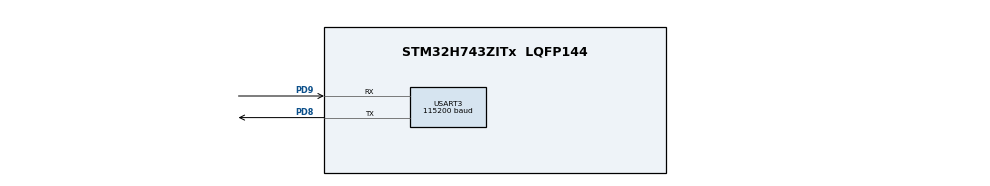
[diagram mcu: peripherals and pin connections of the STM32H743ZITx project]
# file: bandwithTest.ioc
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CORTEX_M7.default_mode_Activation=1
Dma.Request0=USART3_RX
Dma.Request1=USART3_TX
Dma.USART3_RX.0.Direction=DMA_PERIPH_TO_MEMORY
Dma.USART3_RX.0.EventEnable=DISABLE
Dma.USART3_RX.0.FIFOMode=DMA_FIFOMODE_DISABLE
Dma.USART3_RX.0.Instance=DMA1_Stream0
Dma.USART3_RX.0.MemDataAlignment=DMA_MDATAALIGN_BYTE
Dma.USART3_RX.0.MemInc=DMA_MINC_ENABLE
Dma.USART3_RX.0.Mode=DMA_NORMAL
Dma.USART3_RX.0.PeriphDataAlignment=DMA_PDATAALIGN_BYTE
Dma.USART3_RX.0.PeriphInc=DMA_PINC_DISABLE
Dma.USART3_RX.0.Polarity=HAL_DMAMUX_REQ_GEN_RISING
Dma.USART3_RX.0.Priority=DMA_PRIORITY_LOW
Dma.USART3_RX.0.RequestNumber=1
Dma.USART3_RX.0.SignalID=NONE
Dma.USART3_RX.0.SyncEnable=DISABLE
Dma.USART3_RX.0.SyncPolarity=HAL_DMAMUX_SYNC_NO_EVENT
Dma.USART3_RX.0.SyncRequestNumber=1
Dma.USART3_RX.0.SyncSignalID=NONE
Dma.USART3_TX.1.Direction=DMA_MEMORY_TO_PERIPH
Dma.USART3_TX.1.EventEnable=DISABLE
Dma.USART3_TX.1.FIFOMode=DMA_FIFOMODE_DISABLE
Dma.USART3_TX.1.Instance=DMA1_Stream1
Dma.USART3_TX.1.MemDataAlignment=DMA_MDATAALIGN_BYTE
Dma.USART3_TX.1.MemInc=DMA_MINC_ENABLE
Dma.USART3_TX.1.Mode=DMA_NORMAL
Dma.USART3_TX.1.PeriphDataAlignment=DMA_PDATAALIGN_BYTE
Dma.USART3_TX.1.PeriphInc=DMA_PINC_DISABLE
Dma.USART3_TX.1.Polarity=HAL_DMAMUX_REQ_GEN_RISING
Dma.USART3_TX.1.Priority=DMA_PRIORITY_LOW
Dma.USART3_TX.1.RequestNumber=1
Dma.USART3_TX.1.SignalID=NONE
Dma.USART3_TX.1.SyncEnable=DISABLE
Dma.USART3_TX.1.SyncPolarity=HAL_DMAMUX_SYNC_NO_EVENT
Dma.USART3_TX.1.SyncRequestNumber=1
Dma.USART3_TX.1.SyncSignalID=NONE
Mcu.Family=STM32H7
Mcu.Name=STM32H743ZITx
Mcu.Package=LQFP144
NUCLEO-H743ZI2.BUTTON=1
NUCLEO-H743ZI2.LD1=true
NUCLEO-H743ZI2.LD2=true
NUCLEO-H743ZI2.LD3=true
NUCLEO-H743ZI2.VCP=false
NVIC.DMA1_Stream0_IRQn=true\:0\:0\:false\:false\:true\:false\:true\:true
NVIC.DMA1_Stream1_IRQn=true\:0\:0\:false\:false\:true\:false\:true\:true
NVIC.EXTI15_10_IRQn=true\:0\:0\:false\:false\:true\:false\:true\:true
NVIC.PriorityGroup=NVIC_PRIORITYGROUP_4
NVIC.USART3_IRQn=true\:0\:0\:false\:false\:true\:true\:true\:true
PA13\ (JTMS/SWDIO).GPIO_Label=JTMS
PA13\ (JTMS/SWDIO).Mode=Serial_Wire
PA13\ (JTMS/SWDIO).Signal=DEBUG_JTMS-SWDIO
PA14\ (JTCK/SWCLK).GPIO_Label=JTCK
PA14\ (JTCK/SWCLK).Mode=Serial_Wire
PA14\ (JTCK/SWCLK).Signal=DEBUG_JTCK-SWCLK
PC14-OSC32_IN\ (OSC32_IN).Signal=RCC_OSC32_IN
PC15-OSC32_OUT\ (OSC32_OUT).Signal=RCC_OSC32_OUT
PD8.Mode=Asynchronous
PD8.Signal=USART3_TX
PD9.Mode=Asynchronous
PD9.Signal=USART3_RX
PH0-OSC_IN\ (PH0).Mode=HSE-External-Clock-Source
PH0-OSC_IN\ (PH0).Signal=RCC_OSC_IN
PH1-OSC_OUT\ (PH1).Signal=RCC_OSC_OUT
ProjectManager.HeapSize=0x200
ProjectManager.StackSize=0x400
ProjectManager.TargetToolchain=CMake
RCC.ADCFreq_Value=125000000
RCC.APB1Freq_Value=120000000
RCC.APB2Freq_Value=120000000
RCC.APB3Freq_Value=120000000
RCC.APB4Freq_Value=120000000
RCC.CortexFreq_Value=480000000
RCC.D1PPRE=RCC_APB3_DIV2
RCC.D2PPRE1=RCC_APB1_DIV2
RCC.D2PPRE2=RCC_APB2_DIV2
RCC.D3PPRE=RCC_APB4_DIV2
RCC.DIVM1=1
RCC.DIVM2=1
RCC.DIVN1=120
RCC.DIVN2=31
RCC.HCLKFreq_Value=240000000
RCC.HPRE=RCC_HCLK_DIV2
RCC.HSE_VALUE=8000000
RCC.PLL2FRACN=2048
RCC.PLLFRACN=0
RCC.PLLSourceVirtual=RCC_PLLSOURCE_HSE
RCC.SYSCLKFreq_VALUE=480000000
RCC.SYSCLKSource=RCC_SYSCLKSOURCE_PLLCLK
RCC.USART234578CLockSelection=RCC_USART234578CLKSOURCE_PLL2
RCC.USBFreq_Value=480000000
USART3.BaudRate=115200
USART3.VirtualMode-Asynchronous=VM_ASYNC
VP_MEMORYMAP_VS_MEMORYMAP.Mode=CurAppReg
VP_NUCLEO-H743ZI2_VS_BSP_COMMON.Mode=COMMON
board=NUCLEO-H743ZI2

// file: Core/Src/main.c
/* USER CODE BEGIN Header */
/**
  ******************************************************************************
  * @file           : main.c
  * @brief          : Main program body
  ******************************************************************************
  * @attention
  *
  * Copyright (c) 2026 STMicroelectronics.
  * All rights reserved.
  *
  * This software is licensed under terms that can be found in the LICENSE file
  * in the root directory of this software component.
  * If no LICENSE file comes with this software, it is provided AS-IS.
  *
  ******************************************************************************
  */
/* USER CODE END Header */
#include "main.h"
#include "dma.h"
#include "usart.h"
#include "gpio.h"

/* USER CODE BEGIN PD */

  int8_t *RxFrame = (uint8_t *)0x30000000;
  uint8_t *TxFrame = (uint8_t *)0x30010000;
  extern DMA_HandleTypeDef hdma_usart3_rx;
/* USER CODE END PD */

void SystemClock_Config(void);
static void MPU_Config(void);

int main(void)
{

  /* MPU Configuration--------------------------------------------------------*/
  MPU_Config();

  /* MCU Configuration--------------------------------------------------------*/

  /* Reset of all peripherals, Initializes the Flash interface and the Systick. */
  HAL_Init();

  /* Configure the system clock */
  SystemClock_Config();

  /* Initialize all configured peripherals */
  MX_GPIO_Init();
  MX_DMA_Init();
  MX_USART3_UART_Init();
  /* USER CODE BEGIN 2 */
  __HAL_UART_CLEAR_FLAG(&huart3, UART_CLEAR_OREF | UART_CLEAR_NEF | UART_CLEAR_PEF | UART_CLEAR_FEF);

  __HAL_UART_SEND_REQ(&huart3, UART_RXDATA_FLUSH_REQUEST);

  HAL_UARTEx_ReceiveToIdle_DMA(&huart3, RxFrame, FRAME_LENGHT);

  __HAL_DMA_DISABLE_IT(&hdma_usart3_rx, DMA_IT_HT);
  /* USER CODE END 2 */

  /* Initialize leds */
  BSP_LED_Init(LED_GREEN);
  BSP_LED_Init(LED_YELLOW);
  BSP_LED_Init(LED_RED);

  /* Initialize USER push-button, will be used to trigger an interrupt each time it's pressed.*/
  BSP_PB_Init(BUTTON_USER, BUTTON_MODE_EXTI);

  /* Infinite loop */
  while (1)
  {

  }
}

void SystemClock_Config(void)
{
  RCC_OscInitTypeDef RCC_OscInitStruct = {0};
  RCC_ClkInitTypeDef RCC_ClkInitStruct = {0};

  /** Supply configuration update enable
  */
  HAL_PWREx_ConfigSupply(PWR_LDO_SUPPLY);

  /** Configure the main internal regulator output voltage
  */
  __HAL_PWR_VOLTAGESCALING_CONFIG(PWR_REGULATOR_VOLTAGE_SCALE0);

  while(!__HAL_PWR_GET_FLAG(PWR_FLAG_VOSRDY)) {}

  /** Initializes the RCC Oscillators according to the specified parameters
  * in the RCC_OscInitTypeDef structure.
  */
  RCC_OscInitStruct.OscillatorType = RCC_OSCILLATORTYPE_HSE;
  RCC_OscInitStruct.HSEState = RCC_HSE_BYPASS;
  RCC_OscInitStruct.PLL.PLLState = RCC_PLL_ON;
  RCC_OscInitStruct.PLL.PLLSource = RCC_PLLSOURCE_HSE;
  RCC_OscInitStruct.PLL.PLLM = 1;
  RCC_OscInitStruct.PLL.PLLN = 120;
  RCC_OscInitStruct.PLL.PLLP = 2;
  RCC_OscInitStruct.PLL.PLLQ = 2;
  RCC_OscInitStruct.PLL.PLLR = 2;
  RCC_OscInitStruct.PLL.PLLRGE = RCC_PLL1VCIRANGE_3;
  RCC_OscInitStruct.PLL.PLLVCOSEL = RCC_PLL1VCOWIDE;
  RCC_OscInitStruct.PLL.PLLFRACN = 0;
  if (HAL_RCC_OscConfig(&RCC_OscInitStruct) != HAL_OK)
  {
    Error_Handler();
  }

  /** Initializes the CPU, AHB and APB buses clocks
  */
  RCC_ClkInitStruct.ClockType = RCC_CLOCKTYPE_HCLK|RCC_CLOCKTYPE_SYSCLK
                              |RCC_CLOCKTYPE_PCLK1|RCC_CLOCKTYPE_PCLK2
                              |RCC_CLOCKTYPE_D3PCLK1|RCC_CLOCKTYPE_D1PCLK1;
  RCC_ClkInitStruct.SYSCLKSource = RCC_SYSCLKSOURCE_PLLCLK;
  RCC_ClkInitStruct.SYSCLKDivider = RCC_SYSCLK_DIV1;
  RCC_ClkInitStruct.AHBCLKDivider = RCC_HCLK_DIV2;
  RCC_ClkInitStruct.APB3CLKDivider = RCC_APB3_DIV2;
  RCC_ClkInitStruct.APB1CLKDivider = RCC_APB1_DIV2;
  RCC_ClkInitStruct.APB2CLKDivider = RCC_APB2_DIV2;
  RCC_ClkInitStruct.APB4CLKDivider = RCC_APB4_DIV2;

  if (HAL_RCC_ClockConfig(&RCC_ClkInitStruct, FLASH_LATENCY_4) != HAL_OK)
  {
    Error_Handler();
  }
}

 /* MPU Configuration */

void MPU_Config(void)
{
  MPU_Region_InitTypeDef MPU_InitStruct = {0};

  /* Disables the MPU */
  HAL_MPU_Disable();

  /** Initializes and configures the Region and the memory to be protected
  */
  MPU_InitStruct.Enable = MPU_REGION_ENABLE;
  MPU_InitStruct.Number = MPU_REGION_NUMBER0;
  MPU_InitStruct.BaseAddress = 0x0;
  MPU_InitStruct.Size = MPU_REGION_SIZE_4GB;
  MPU_InitStruct.SubRegionDisable = 0x87;
  MPU_InitStruct.TypeExtField = MPU_TEX_LEVEL0;
  MPU_InitStruct.AccessPermission = MPU_REGION_NO_ACCESS;
  MPU_InitStruct.DisableExec = MPU_INSTRUCTION_ACCESS_DISABLE;
  MPU_InitStruct.IsShareable = MPU_ACCESS_SHAREABLE;
  MPU_InitStruct.IsCacheable = MPU_ACCESS_NOT_CACHEABLE;
  MPU_InitStruct.IsBufferable = MPU_ACCESS_NOT_BUFFERABLE;

  HAL_MPU_ConfigRegion(&MPU_InitStruct);
  /* Enables the MPU */
  HAL_MPU_Enable(MPU_PRIVILEGED_DEFAULT);

}

void Error_Handler(void)
{
  __disable_irq();
  while (1)
  {
  }
}
